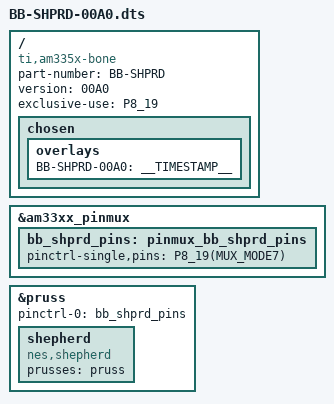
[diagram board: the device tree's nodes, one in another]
/dts-v1/;
/plugin/;
#include "am335x_pinctrl.h"

/*
// future-reference, gpio.h contains: BONE_P8_03, etc
#include <dt-bindings/gpio/gpio.h>
// future-reference, omap.h contains: MUX_MODE#, PULL_UP, INPUT_EN, AM33XX_IOPAD, AM33XX_PADCONF, etc
#include <dt-bindings/pinctrl/omap.h>
*/


/ {
   // note: (older) "ti,beaglebone" types seem to be working as well for v4.19.x-ti, but this is more future-proof
   compatible = "ti,am335x-bone", "ti,am335x-bone-black", "ti,am335x-bone-green";

   part-number = "BB-SHPRD";
   version = "00A0";

   /* This overlay uses the following resources */
   exclusive-use = "P8_19"; /* 	BTN Led */

   /* Check Table 9-60 in am335x TRM */

   /* Helper to show loaded overlays under: /proc/device-tree/chosen/overlays/  */
   /* Note:
        - root-path and "chosen" seem to produce a warning with dtc, internet is not helpful
        - this is the reference solution chosen by: https://github.com/RobertCNelson/bb.org-overlays
   */
   fragment@0 {
      target-path="/";
      __overlay__ {
         chosen {
            overlays {
               BB-SHPRD-00A0 = __TIMESTAMP__;
            };
         };
      };
   };


   fragment@1 {
      target = <&am33xx_pinmux>;
      __overlay__ {
         bb_shprd_pins: pinmux_bb_shprd_pins {
            pinctrl-single,pins = <

            P8_19(MUX_MODE7)                // gpio0[22]

            >;
         };
      };
   };

   fragment@2 {
       target = <&pruss>;
       __overlay__ {
            status = "okay";
            pinctrl-names = "default";
            pinctrl-0 = <&bb_shprd_pins>;
            shepherd{
               compatible = "nes,shepherd";
               prusses = <&pruss>;
            };
       };
   };

};
